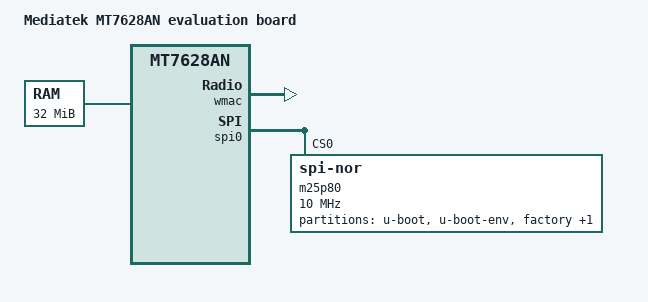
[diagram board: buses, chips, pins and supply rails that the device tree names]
/dts-v1/;

#include "mt7628an.dtsi"

/ {
	compatible = "mediatek,mt7628an-eval-board", "mediatek,mt7628an-soc";
	model = "Mediatek MT7628AN evaluation board";

	memory@0 {
		device_type = "memory";
		reg = <0x0 0x2000000>;
	};
};

&pinctrl {
	state_default: pinctrl0 {
		gpio {
			ralink,group = "i2c", "jtag";
			ralink,function = "gpio";
		};
	};
};

&wmac {
	status = "okay";
};

&spi0 {
	status = "okay";

	m25p80@0 {
		#address-cells = <1>;
		#size-cells = <1>;
		compatible = "jedec,spi-nor";
		reg = <0>;
		linux,modalias = "m25p80", "en25q64";
		spi-max-frequency = <10000000>;
		m25p,chunked-io = <32>;

		partition@0 {
			label = "u-boot";
			reg = <0x0 0x30000>;
			read-only;
		};

		partition@30000 {
			label = "u-boot-env";
			reg = <0x30000 0x10000>;
			read-only;
		};

		factory: partition@40000 {
			label = "factory";
			reg = <0x40000 0x10000>;
			read-only;
		};

		partition@50000 {
			label = "firmware";
			reg = <0x50000 0x7b0000>;
		};
	};
};

&wmac {
	status = "okay";
};
